VERSION ""

NS_ :

BS_:

BU_:

BO_ 61444 EEC1: 8 Vector__XXX
 SG_ SPN190_EngineSpeed : 24|16@1+ (0.125,0) [0|8000] "rpm"  Vector__XXX
 SG_ SPN513_ActualEnginePercentTorque : 8|8@1+ (1,-125) [-125|125] "%"  Vector__XXX

BO_ 65262 EEC2: 8 Vector__XXX
 SG_ SPN558_AcceleratorPedalPosition1 : 8|8@1+ (0.4,0) [0|100] "%"  Vector__XXX
 SG_ SPN91_AcceleratorPedalPosition2 : 16|8@1+ (0.4,0) [0|100] "%"  Vector__XXX

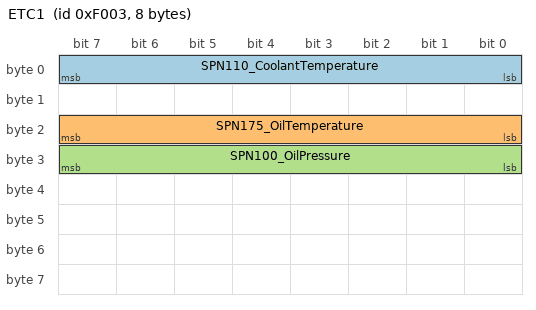
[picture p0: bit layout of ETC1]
BO_ 61443 ETC1: 8 Vector__XXX
 SG_ SPN110_CoolantTemperature : 0|8@1+ (1,-40) [-40|210] "degC"  Vector__XXX
 SG_ SPN175_OilTemperature : 16|8@1+ (1,-273) [-273|1735] "degC"  Vector__XXX
 SG_ SPN100_OilPressure : 24|8@1+ (4,0) [0|1000] "kPa"  Vector__XXX

BO_ 65276 DASH: 8 Vector__XXX
 SG_ SPN96_FuelLevel : 8|8@1+ (0.4,0) [0|100] "%"  Vector__XXX
 SG_ SPN183_FuelRate : 16|16@1+ (0.05,0) [0|3212.75] "L/h"  Vector__XXX
